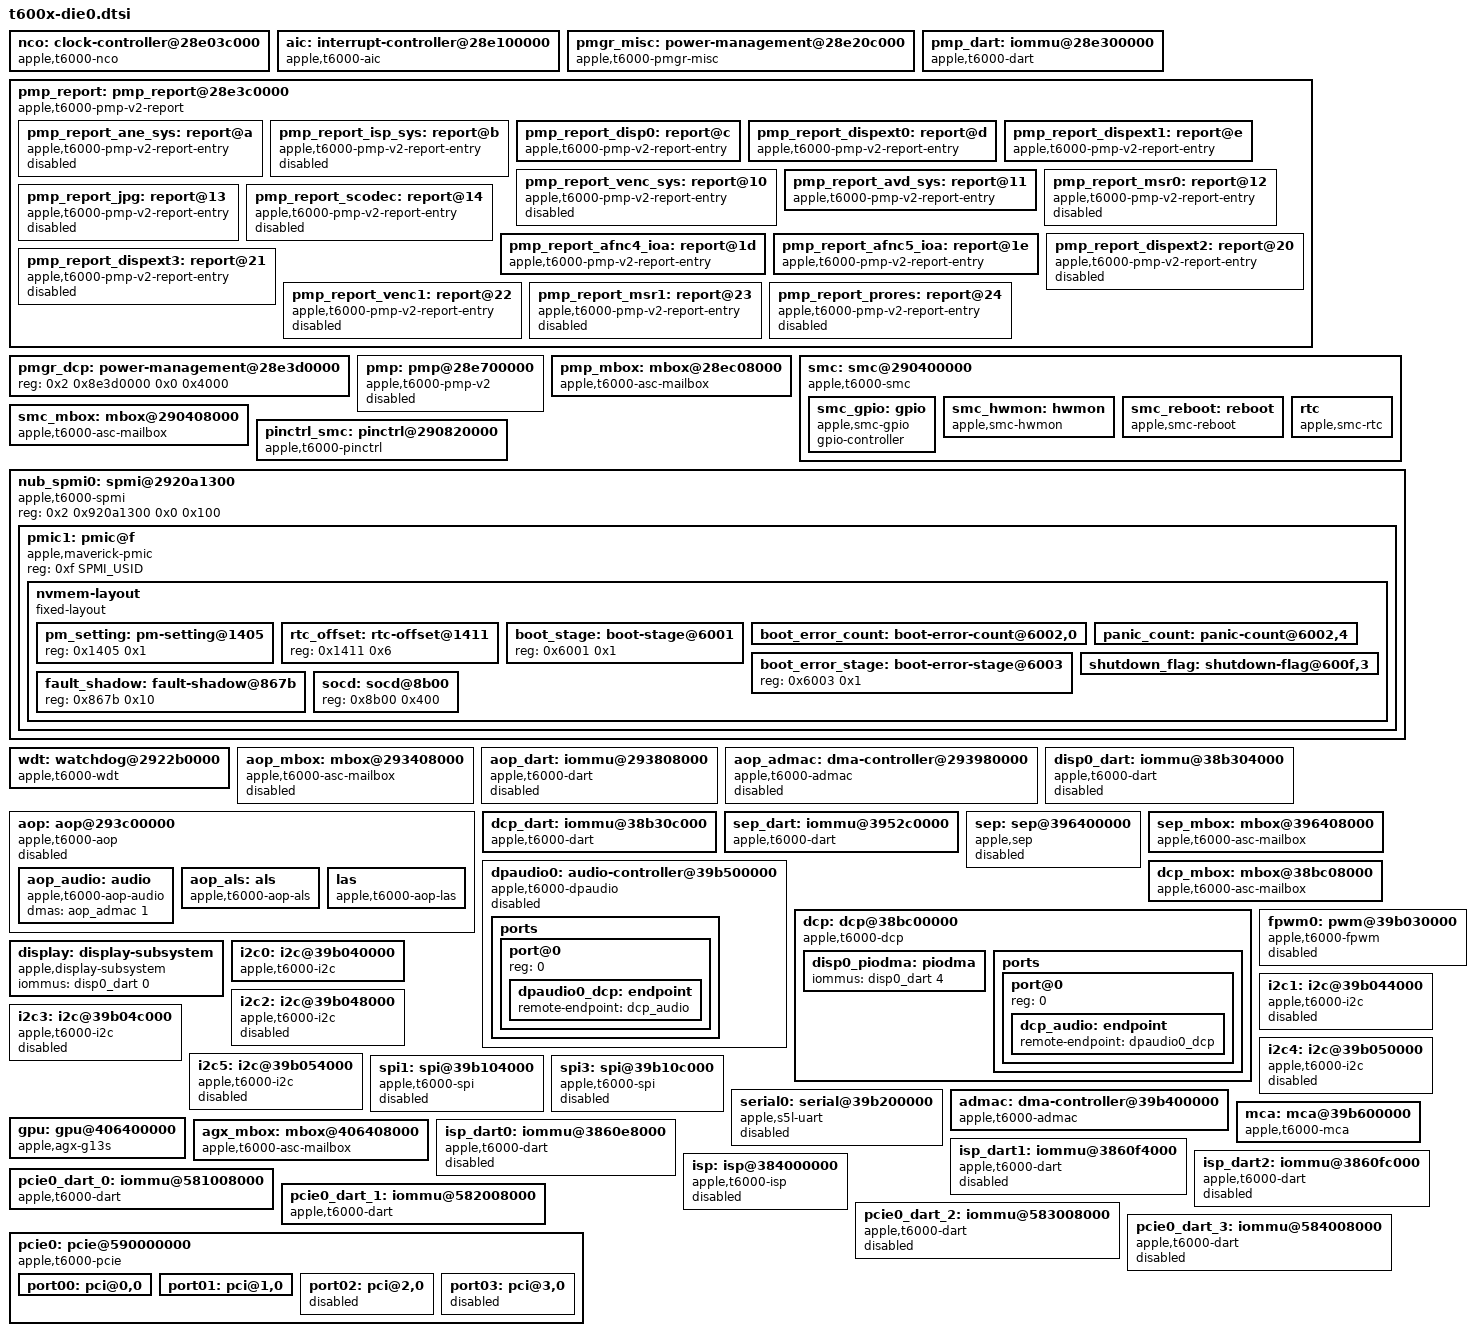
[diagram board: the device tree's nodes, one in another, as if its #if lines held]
// SPDX-License-Identifier: GPL-2.0+ OR MIT
/*
 * Devices used on die 0 on the Apple T6002 "M1 Ultra" SoC and present on
 * Apple T6000 / T6001 "M1 Pro" / "M1 Max".
 *
 * Copyright The Asahi Linux Contributors
 */


	nco: clock-controller@28e03c000 {
		compatible = "apple,t6000-nco", "apple,nco";
		reg = <0x2 0x8e03c000 0x0 0x14000>;
		clocks = <&nco_clkref>;
		#clock-cells = <1>;
	};

	aic: interrupt-controller@28e100000 {
		compatible = "apple,t6000-aic", "apple,aic2";
		#interrupt-cells = <4>;
		interrupt-controller;
		reg = <0x2 0x8e100000 0x0 0xc000>,
			<0x2 0x8e10c000 0x0 0x4>;
		reg-names = "core", "event";
		power-domains = <&ps_aic>;
	};

	pmgr_misc: power-management@28e20c000 {
		compatible = "apple,t6000-pmgr-misc";
		#address-cells = <1>;
		#size-cells = <1>;
		reg = <0x2 0x8e20c000 0 0x400>,
			<0x2 0x8e20c800 0 0x400>;
		reg-names = "fabric-ps", "dcs-ps";
		apple,dcs-min-ps = <7>;
	};

	pmp_dart: iommu@28e300000 {
		compatible = "apple,t6000-dart";
		reg = <0x2 0x8e300000 0x0 0x4000>;
		#iommu-cells = <1>;
		interrupt-parent = <&aic>;
		interrupts = <AIC_IRQ 0 1010 IRQ_TYPE_LEVEL_HIGH>;
		power-domains = <&ps_pmp>;
	};

	pmp_report: pmp_report@28e3c0000 {
		compatible = "apple,t6000-pmp-v2-report";
		reg = <0x2 0x8e3c0000 0x0 0x20000>;
		power-domains = <&ps_pms_sram>;
		#address-cells = <1>;
		#size-cells = <0>;

		pmp_report_ane_sys: report@a {
			compatible = "apple,t6000-pmp-v2-report-entry";
			reg = <0xa>;
			label = "pmp-ane-sys";
			#power-domain-cells = <0>;
			power-domains = <&ps_ane_sys>;
			status = "disabled";
		};

		pmp_report_isp_sys: report@b {
			compatible = "apple,t6000-pmp-v2-report-entry";
			reg = <0xb>;
			label = "pmp-isp-sys";
			#power-domain-cells = <0>;
			power-domains = <&ps_isp_sys>;
			status = "disabled";
		};

		pmp_report_disp0: report@c {
			compatible = "apple,t6000-pmp-v2-report-entry";
			reg = <0xc>;
			label = "pmp-disp0";
			#power-domain-cells = <0>;
			power-domains = <&ps_disp0_cpu0>;
			apple,always-on;
		};

		pmp_report_dispext0: report@d {
			compatible = "apple,t6000-pmp-v2-report-entry";
			reg = <0xd>;
			label = "pmp-dispext0";
			#power-domain-cells = <0>;
			power-domains = <&ps_dispext0_cpu0>;
			apple,always-on;
		};

		pmp_report_dispext1: report@e {
			compatible = "apple,t6000-pmp-v2-report-entry";
			reg = <0xe>;
			label = "pmp-dispext1";
			#power-domain-cells = <0>;
			power-domains = <&ps_dispext1_cpu0>;
		};

		pmp_report_venc_sys: report@10 {
			compatible = "apple,t6000-pmp-v2-report-entry";
			reg = <0x10>;
			label = "pmp-venc-sys";
			#power-domain-cells = <0>;
			power-domains = <&ps_venc_sys>;
			status = "disabled";
		};

		pmp_report_avd_sys: report@11 {
			compatible = "apple,t6000-pmp-v2-report-entry";
			reg = <0x11>;
			label = "pmp-avd-sys";
			#power-domain-cells = <0>;
			power-domains = <&ps_avd_sys>;
		};

		pmp_report_msr0: report@12 {
			compatible = "apple,t6000-pmp-v2-report-entry";
			reg = <0x12>;
			label = "pmp-msr0";
			#power-domain-cells = <0>;
			power-domains = <&ps_msr0>;
			status = "disabled";
		};

		pmp_report_jpg: report@13 {
			compatible = "apple,t6000-pmp-v2-report-entry";
			reg = <0x13>;
			label = "pmp-jpg";
			#power-domain-cells = <0>;
			power-domains = <&ps_jpg>;
			status = "disabled";
		};

		pmp_report_scodec: report@14 {
			compatible = "apple,t6000-pmp-v2-report-entry";
			reg = <0x14>;
			label = "pmp-scodec";
			#power-domain-cells = <0>;
			power-domains = <&ps_scodec>;
			status = "disabled";
		};

		pmp_report_afnc4_ioa: report@1d {
			compatible = "apple,t6000-pmp-v2-report-entry";
			reg = <0x1d>;
			label = "pmp-afnc4-ioa";
			#power-domain-cells = <0>;
			apple,always-on;
		};

		pmp_report_afnc5_ioa: report@1e {
			compatible = "apple,t6000-pmp-v2-report-entry";
			reg = <0x1e>;
			label = "pmp-afnc5-ioa";
			#power-domain-cells = <0>;
			apple,always-on;
		};

		pmp_report_dispext2: report@20 {
			compatible = "apple,t6000-pmp-v2-report-entry";
			reg = <0x20>;
			label = "pmp-dispext2";
			#power-domain-cells = <0>;
			power-domains = <&ps_dispext2_cpu0>;
			status = "disabled";
		};

		pmp_report_dispext3: report@21 {
			compatible = "apple,t6000-pmp-v2-report-entry";
			reg = <0x21>;
			label = "pmp-dispext3";
			#power-domain-cells = <0>;
			power-domains = <&ps_dispext3_cpu0>;
			status = "disabled";
		};

		pmp_report_venc1: report@22 {
			compatible = "apple,t6000-pmp-v2-report-entry";
			reg = <0x22>;
			label = "pmp-venc1";
			#power-domain-cells = <0>;
			power-domains = <&ps_venc1_sys>;
			status = "disabled";
		};

		pmp_report_msr1: report@23 {
			compatible = "apple,t6000-pmp-v2-report-entry";
			reg = <0x23>;
			label = "pmp-msr1";
			#power-domain-cells = <0>;
			power-domains = <&ps_msr1>;
			status = "disabled";
		};

		pmp_report_prores: report@24 {
			compatible = "apple,t6000-pmp-v2-report-entry";
			reg = <0x24>;
			label = "pmp-prores";
			#power-domain-cells = <0>;
			power-domains = <&ps_prores>;
			status = "disabled";
		};
	};

	pmgr_dcp: power-management@28e3d0000 {
		reg = <0x2 0x8e3d0000 0x0 0x4000>;
		reg-names = "dcp-fw-pmgr";
		#apple,bw-scratch-cells = <3>;
	};

	pmp: pmp@28e700000 {
		compatible = "apple,t6000-pmp-v2";
		reg = <0x2 0x8e700000 0x0 0x100000>,
			<0x2 0x8ec00000 0x0 0x4000>;
		reg-names = "pmp", "asc";
		mboxes = <&pmp_mbox>;
		mbox-names = "mbox";
		iommus = <&pmp_dart 0>;
		power-domains = <&ps_pmp>;
		status = "disabled";
	};

	pmp_mbox: mbox@28ec08000 {
		compatible = "apple,t6000-asc-mailbox", "apple,asc-mailbox-v4";
		reg = <0x2 0x8ec08000 0x0 0x4000>;
		interrupt-parent = <&aic>;
		interrupts = <AIC_IRQ 0 1006 IRQ_TYPE_LEVEL_HIGH>,
			<AIC_IRQ 0 1007 IRQ_TYPE_LEVEL_HIGH>,
			<AIC_IRQ 0 1008 IRQ_TYPE_LEVEL_HIGH>,
			<AIC_IRQ 0 1009 IRQ_TYPE_LEVEL_HIGH>;
		interrupt-names = "send-empty", "send-not-empty",
			"recv-empty", "recv-not-empty";
		#mbox-cells = <0>;
		power-domains = <&ps_pmp>, <&ps_pms_sram>;
	};

	smc: smc@290400000 {
		compatible = "apple,t6000-smc", "apple,smc";
		reg = <0x2 0x90400000 0x0 0x4000>,
			<0x2 0x91e00000 0x0 0x100000>;
		reg-names = "smc", "sram";
		mboxes = <&smc_mbox>;

		smc_gpio: gpio {
			compatible = "apple,smc-gpio";
			gpio-controller;
			#gpio-cells = <2>;
		};

		smc_hwmon: hwmon {
			compatible = "apple,smc-hwmon";
		};

		smc_reboot: reboot {
			compatible = "apple,smc-reboot";
			nvmem-cells = <&shutdown_flag>, <&boot_stage>,
				<&boot_error_count>, <&panic_count>, <&pm_setting>;
			nvmem-cell-names = "shutdown_flag", "boot_stage",
				"boot_error_count", "panic_count", "pm_setting";
		};

		rtc {
			compatible = "apple,smc-rtc";
			nvmem-cells = <&rtc_offset>;
			nvmem-cell-names = "rtc_offset";
		};
	};

	smc_mbox: mbox@290408000 {
		compatible = "apple,t6000-asc-mailbox", "apple,asc-mailbox-v4";
		reg = <0x2 0x90408000 0x0 0x4000>;
		interrupt-parent = <&aic>;
		interrupts = <AIC_IRQ 0 754 IRQ_TYPE_LEVEL_HIGH>,
			<AIC_IRQ 0 755 IRQ_TYPE_LEVEL_HIGH>,
			<AIC_IRQ 0 756 IRQ_TYPE_LEVEL_HIGH>,
			<AIC_IRQ 0 757 IRQ_TYPE_LEVEL_HIGH>;
		interrupt-names = "send-empty", "send-not-empty",
			"recv-empty", "recv-not-empty";
		#mbox-cells = <0>;
	};

	pinctrl_smc: pinctrl@290820000 {
		compatible = "apple,t6000-pinctrl", "apple,pinctrl";
		reg = <0x2 0x90820000 0x0 0x4000>;

		gpio-controller;
		#gpio-cells = <2>;
		gpio-ranges = <&pinctrl_smc 0 0 30>;
		apple,npins = <30>;

		interrupt-controller;
		#interrupt-cells = <2>;
		interrupt-parent = <&aic>;
		interrupts = <AIC_IRQ 0 743 IRQ_TYPE_LEVEL_HIGH>,
				<AIC_IRQ 0 744 IRQ_TYPE_LEVEL_HIGH>,
				<AIC_IRQ 0 745 IRQ_TYPE_LEVEL_HIGH>,
				<AIC_IRQ 0 746 IRQ_TYPE_LEVEL_HIGH>,
				<AIC_IRQ 0 747 IRQ_TYPE_LEVEL_HIGH>,
				<AIC_IRQ 0 748 IRQ_TYPE_LEVEL_HIGH>,
				<AIC_IRQ 0 749 IRQ_TYPE_LEVEL_HIGH>;
	};

	nub_spmi0: spmi@2920a1300 {
		compatible = "apple,t6000-spmi", "apple,spmi";
		reg = <0x2 0x920a1300 0x0 0x100>;
		#address-cells = <2>;
		#size-cells = <0>;

		pmic1: pmic@f {
			compatible = "apple,maverick-pmic", "apple,spmi-nvmem";
			reg = <0xf SPMI_USID>;

			nvmem-layout {
				compatible = "fixed-layout";
				#address-cells = <1>;
				#size-cells = <1>;

				pm_setting: pm-setting@1405 {
					reg = <0x1405 0x1>;
				};

				rtc_offset: rtc-offset@1411 {
					reg = <0x1411 0x6>;
				};

				boot_stage: boot-stage@6001 {
					reg = <0x6001 0x1>;
				};

				boot_error_count: boot-error-count@6002,0 {
					reg = <0x6002 0x1>;
					bits = <0 4>;
				};

				panic_count: panic-count@6002,4 {
					reg = <0x6002 0x1>;
					bits = <4 4>;
				};

				boot_error_stage: boot-error-stage@6003 {
					reg = <0x6003 0x1>;
				};

				shutdown_flag: shutdown-flag@600f,3 {
					reg = <0x600f 0x1>;
					bits = <3 1>;
				};

				fault_shadow: fault-shadow@867b {
					reg = <0x867b 0x10>;
				};

				socd: socd@8b00 {
					reg = <0x8b00 0x400>;
				};
			};
		};
	};

	wdt: watchdog@2922b0000 {
		compatible = "apple,t6000-wdt", "apple,wdt";
		reg = <0x2 0x922b0000 0x0 0x4000>;
		clocks = <&clkref>;
		interrupt-parent = <&aic>;
		interrupts = <AIC_IRQ 0 631 IRQ_TYPE_LEVEL_HIGH>;
	};

	aop_mbox: mbox@293408000 {
		compatible = "apple,t6000-asc-mailbox", "apple,asc-mailbox-v4";
		reg = <0x2 0x93408000 0x0 0x4000>;
		interrupt-parent = <&aic>;
		interrupts = <AIC_IRQ 0 582 IRQ_TYPE_LEVEL_HIGH>,
			<AIC_IRQ 0 583 IRQ_TYPE_LEVEL_HIGH>,
			<AIC_IRQ 0 584 IRQ_TYPE_LEVEL_HIGH>,
			<AIC_IRQ 0 585 IRQ_TYPE_LEVEL_HIGH>;
		interrupt-names = "send-empty", "send-not-empty",
			"recv-empty", "recv-not-empty";
		#mbox-cells = <0>;
		status = "disabled";
	};

	aop_dart: iommu@293808000 {
		compatible = "apple,t6000-dart";
		reg = <0x2 0x93808000 0x0 0x4000>;
		#iommu-cells = <1>;
		interrupt-parent = <&aic>;
		interrupts = <AIC_IRQ 0 597 IRQ_TYPE_LEVEL_HIGH>;
		status = "disabled";
	};

	aop_admac: dma-controller@293980000 {
		compatible = "apple,t6000-admac", "apple,admac";
		reg = <0x2 0x93980000 0x0 0x34000>;
		#dma-cells = <1>;
		dma-channels = <16>;
		interrupts-extended = <0>,
				      <0>,
				      <&aic AIC_IRQ 0 600 IRQ_TYPE_LEVEL_HIGH>,
				      <0>;
		iommus = <&aop_dart 7>;
		status = "disabled";
	};

	aop: aop@293c00000 {
		compatible = "apple,t6000-aop";
		reg = <0x2 0x93c00000 0x0 0x250000>,
		      <0x2 0x93400000 0x0 0x6c000>;
		mboxes = <&aop_mbox>;
		mbox-names = "mbox";
		iommus = <&aop_dart 0>;

		status = "disabled";

		aop_audio: audio {
			compatible = "apple,t6000-aop-audio", "apple,aop-audio";
			dmas = <&aop_admac 1>;
			dma-names = "dma";
		};

		aop_als: als {
			compatible = "apple,t6000-aop-als", "apple,aop-als";
			// intentionally empty
		};

		las {
			compatible = "apple,t6000-aop-las", "apple,aop-las";
		};
	};

	disp0_dart: iommu@38b304000 {
		compatible = "apple,t6000-dart";
		reg = <0x3 0x8b304000 0x0 0x4000>;
		#iommu-cells = <1>;
		interrupt-parent = <&aic>;
		interrupts = <AIC_IRQ 0 821 IRQ_TYPE_LEVEL_HIGH>;
		status = "disabled";
		power-domains = <&ps_disp0_cpu0>;
		apple,dma-range = <0x0 0x0 0x0 0xfc000000>;
	};

	dcp_dart: iommu@38b30c000 {
		compatible = "apple,t6000-dart";
		reg = <0x3 0x8b30c000 0x0 0x4000>;
		#iommu-cells = <1>;
		interrupt-parent = <&aic>;
		interrupts = <AIC_IRQ 0 821 IRQ_TYPE_LEVEL_HIGH>;
		power-domains = <&ps_disp0_cpu0>;
		apple,dma-range = <0x1f0 0x0 0x0 0xfc000000>;
	};

	sep_dart: iommu@3952c0000 {
		compatible = "apple,t6000-dart";
		reg = <0x3 0x952c0000 0x0 0x4000>;
		#iommu-cells = <1>;
		interrupt-parent = <&aic>;
		interrupts = <AIC_IRQ 0 551 IRQ_TYPE_LEVEL_HIGH>;
	};

	sep: sep@396400000 {
		compatible = "apple,sep";
		reg = <0x3 0x96400000 0x0 0x6C000>;
		mboxes = <&sep_mbox>;
		mbox-names = "mbox";
		iommus = <&sep_dart 0>;
		power-domains = <&ps_sep>;
		status = "disabled";
	};

	sep_mbox: mbox@396408000 {
		compatible = "apple,t6000-asc-mailbox", "apple,asc-mailbox-v4";
		reg = <0x3 0x96408000 0x0 0x4000>;
		interrupt-parent = <&aic>;
		interrupts = <AIC_IRQ 0 545 IRQ_TYPE_LEVEL_HIGH>,
			<AIC_IRQ 0 546 IRQ_TYPE_LEVEL_HIGH>,
			<AIC_IRQ 0 547 IRQ_TYPE_LEVEL_HIGH>,
			<AIC_IRQ 0 548 IRQ_TYPE_LEVEL_HIGH>;
		interrupt-names = "send-empty", "send-not-empty",
			"recv-empty", "recv-not-empty";
		#mbox-cells = <0>;
	};

	dpaudio0: audio-controller@39b500000 {
		compatible = "apple,t6000-dpaudio", "apple,dpaudio";
		reg = <0x3 0x9b500000 0x0 0x4000>;
		dmas = <&sio 0x64>;
		dma-names = "tx";
		power-domains = <&ps_dpa0>;
		reset-domains = <&ps_dpa0>;
		status = "disabled";

		ports {
			#address-cells = <1>;
			#size-cells = <0>;
			port@0 {
				reg = <0>;
				dpaudio0_dcp: endpoint {
					remote-endpoint = <&dcp_audio>;
				};
			};
		};
	};

	dcp_mbox: mbox@38bc08000 {
		compatible = "apple,t6000-asc-mailbox", "apple,asc-mailbox-v4";
		reg = <0x3 0x8bc08000 0x0 0x4000>;
		interrupt-parent = <&aic>;
		interrupts = <AIC_IRQ 0 842 IRQ_TYPE_LEVEL_HIGH>,
			<AIC_IRQ 0 843 IRQ_TYPE_LEVEL_HIGH>,
			<AIC_IRQ 0 844 IRQ_TYPE_LEVEL_HIGH>,
			<AIC_IRQ 0 845 IRQ_TYPE_LEVEL_HIGH>;
		interrupt-names = "send-empty", "send-not-empty",
			"recv-empty", "recv-not-empty";
		#mbox-cells = <0>;
		power-domains = <&ps_disp0_cpu0>;
	};

	dcp: dcp@38bc00000 {
		compatible = "apple,t6000-dcp", "apple,dcp";
		mboxes = <&dcp_mbox>;
		mbox-names = "mbox";
		iommus = <&dcp_dart 0>;

		reg-names = "coproc", "disp-0", "disp-1", "disp-2", "disp-3";
		reg = <0x3 0x8bc00000 0x0 0x4000>,
			<0x3 0x8a000000 0x0 0x3000000>,
			<0x3 0x8b320000 0x0 0x4000>,
			<0x3 0x8b344000 0x0 0x4000>,
			<0x3 0x8b800000 0x0 0x800000>;
		apple,bw-scratch = <&pmgr_dcp 0 4 0x988>;
		#ifdef APPLE_USE_PMP
		power-domains = <&pmp_report_disp0>;
		#else
		power-domains = <&ps_disp0_cpu0>;
		#endif
		resets = <&ps_disp0_cpu0>;
		clocks = <&clk_disp0>;
		phandle = <&dcp>;
		// required bus properties for 'piodma' subdevice
		#address-cells = <2>;
		#size-cells = <2>;

		disp0_piodma: piodma {
			iommus = <&disp0_dart 4>;
			phandle = <&disp0_piodma>;
		};

		ports {
			#address-cells = <1>;
			#size-cells = <0>;
			port@0 {
				reg = <0>;
				dcp_audio: endpoint {
					remote-endpoint = <&dpaudio0_dcp>;
				};
			};
		};
	};

	display: display-subsystem {
		compatible = "apple,display-subsystem";
		iommus = <&disp0_dart 0>;
		/* generate phandle explicitly for use in loader */
		phandle = <&display>;
	};

	fpwm0: pwm@39b030000 {
		compatible = "apple,t6000-fpwm", "apple,s5l-fpwm";
		reg = <0x3 0x9b030000 0x0 0x4000>;
		power-domains = <&ps_fpwm0>;
		clocks = <&clkref>;
		#pwm-cells = <2>;
		status = "disabled";
	};

	i2c0: i2c@39b040000 {
		compatible = "apple,t6000-i2c", "apple,i2c";
		reg = <0x3 0x9b040000 0x0 0x4000>;
		clocks = <&clkref>;
		interrupt-parent = <&aic>;
		interrupts = <AIC_IRQ 0 1119 IRQ_TYPE_LEVEL_HIGH>;
		pinctrl-0 = <&i2c0_pins>;
		pinctrl-names = "default";
		power-domains = <&ps_i2c0>;
		#address-cells = <0x1>;
		#size-cells = <0x0>;
	};

	i2c1: i2c@39b044000 {
		compatible = "apple,t6000-i2c", "apple,i2c";
		reg = <0x3 0x9b044000 0x0 0x4000>;
		clocks = <&clkref>;
		interrupt-parent = <&aic>;
		interrupts = <AIC_IRQ 0 1120 IRQ_TYPE_LEVEL_HIGH>;
		pinctrl-0 = <&i2c1_pins>;
		pinctrl-names = "default";
		power-domains = <&ps_i2c1>;
		#address-cells = <0x1>;
		#size-cells = <0x0>;
		status = "disabled";
	};

	i2c2: i2c@39b048000 {
		compatible = "apple,t6000-i2c", "apple,i2c";
		reg = <0x3 0x9b048000 0x0 0x4000>;
		clocks = <&clkref>;
		interrupt-parent = <&aic>;
		interrupts = <AIC_IRQ 0 1121 IRQ_TYPE_LEVEL_HIGH>;
		pinctrl-0 = <&i2c2_pins>;
		pinctrl-names = "default";
		power-domains = <&ps_i2c2>;
		#address-cells = <0x1>;
		#size-cells = <0x0>;
		status = "disabled";
	};

	i2c3: i2c@39b04c000 {
		compatible = "apple,t6000-i2c", "apple,i2c";
		reg = <0x3 0x9b04c000 0x0 0x4000>;
		clocks = <&clkref>;
		interrupt-parent = <&aic>;
		interrupts = <AIC_IRQ 0 1122 IRQ_TYPE_LEVEL_HIGH>;
		pinctrl-0 = <&i2c3_pins>;
		pinctrl-names = "default";
		power-domains = <&ps_i2c3>;
		#address-cells = <0x1>;
		#size-cells = <0x0>;
		status = "disabled";
	};

	i2c4: i2c@39b050000 {
		compatible = "apple,t6000-i2c", "apple,i2c";
		reg = <0x3 0x9b050000 0x0 0x4000>;
		clocks = <&clkref>;
		interrupt-parent = <&aic>;
		interrupts = <AIC_IRQ 0 1123 IRQ_TYPE_LEVEL_HIGH>;
		pinctrl-0 = <&i2c4_pins>;
		pinctrl-names = "default";
		power-domains = <&ps_i2c4>;
		#address-cells = <0x1>;
		#size-cells = <0x0>;
		status = "disabled";
	};

	i2c5: i2c@39b054000 {
		compatible = "apple,t6000-i2c", "apple,i2c";
		reg = <0x3 0x9b054000 0x0 0x4000>;
		clocks = <&clkref>;
		interrupt-parent = <&aic>;
		interrupts = <AIC_IRQ 0 1124 IRQ_TYPE_LEVEL_HIGH>;
		pinctrl-0 = <&i2c5_pins>;
		pinctrl-names = "default";
		power-domains = <&ps_i2c5>;
		#address-cells = <0x1>;
		#size-cells = <0x0>;
		status = "disabled";
	};

	spi1: spi@39b104000 {
		compatible = "apple,t6000-spi", "apple,spi";
		reg = <0x3 0x9b104000 0x0 0x4000>;
		interrupt-parent = <&aic>;
		interrupts = <AIC_IRQ 0 1107 IRQ_TYPE_LEVEL_HIGH>;
		#address-cells = <1>;
		#size-cells = <0>;
		clocks = <&clk_200m>;
		pinctrl-0 = <&spi1_pins>;
		pinctrl-names = "default";
		power-domains = <&ps_spi1>;
		status = "disabled";
	};

	spi3: spi@39b10c000 {
		compatible = "apple,t6000-spi", "apple,spi";
		reg = <0x3 0x9b10c000 0x0 0x4000>;
		interrupt-parent = <&aic>;
		interrupts = <AIC_IRQ 0 1109 IRQ_TYPE_LEVEL_HIGH>;
		#address-cells = <1>;
		#size-cells = <0>;
		clocks = <&clkref>;
		pinctrl-0 = <&spi3_pins>;
		pinctrl-names = "default";
		power-domains = <&ps_spi3>;
		status = "disabled";
	};

	serial0: serial@39b200000 {
		compatible = "apple,s5l-uart";
		reg = <0x3 0x9b200000 0x0 0x1000>;
		reg-io-width = <4>;
		interrupt-parent = <&aic>;
		interrupts = <AIC_IRQ 0 1097 IRQ_TYPE_LEVEL_HIGH>;
		/*
		 * TODO: figure out the clocking properly, there may
		 * be a third selectable clock.
		 */
		clocks = <&clkref>, <&clkref>;
		clock-names = "uart", "clk_uart_baud0";
		power-domains = <&ps_uart0>;
		status = "disabled";
	};

	admac: dma-controller@39b400000 {
		compatible = "apple,t6000-admac", "apple,admac";
		reg = <0x3 0x9b400000 0x0 0x34000>;
		#dma-cells = <1>;
		dma-channels = <16>;
		interrupts-extended = <0>,
				      <&aic AIC_IRQ 0 1118 IRQ_TYPE_LEVEL_HIGH>,
				      <0>,
				      <0>;
		iommus = <&sio_dart_0 2>, <&sio_dart_1 2>;
		power-domains = <&ps_sio_adma>;
		resets = <&ps_audio_p>;
	};

	mca: mca@39b600000 {
		compatible = "apple,t6000-mca", "apple,mca";
		reg = <0x3 0x9b600000 0x0 0x10000>,
		      <0x3 0x9b500000 0x0 0x20000>;
		clocks = <&nco 0>, <&nco 1>, <&nco 2>, <&nco 3>;
		dmas = <&admac 0>, <&admac 1>, <&admac 2>, <&admac 3>,
		       <&admac 4>, <&admac 5>, <&admac 6>, <&admac 7>,
		       <&admac 8>, <&admac 9>, <&admac 10>, <&admac 11>,
		       <&admac 12>, <&admac 13>, <&admac 14>, <&admac 15>;
		dma-names = "tx0a", "rx0a", "tx0b", "rx0b",
			    "tx1a", "rx1a", "tx1b", "rx1b",
			    "tx2a", "rx2a", "tx2b", "rx2b",
			    "tx3a", "rx3a", "tx3b", "rx3b";
		interrupt-parent = <&aic>;
		interrupts = <AIC_IRQ 0 1111 IRQ_TYPE_LEVEL_HIGH>,
			     <AIC_IRQ 0 1112 IRQ_TYPE_LEVEL_HIGH>,
			     <AIC_IRQ 0 1113 IRQ_TYPE_LEVEL_HIGH>,
			     <AIC_IRQ 0 1114 IRQ_TYPE_LEVEL_HIGH>;
		power-domains = <&ps_audio_p>, <&ps_mca0>, <&ps_mca1>,
				<&ps_mca2>, <&ps_mca3>;
		resets = <&ps_audio_p>;
		#sound-dai-cells = <1>;
	};

	gpu: gpu@406400000 {
		compatible = "apple,agx-g13s";
		reg = <0x4 0x6400000 0 0x40000>,
			<0x4 0x4000000 0 0x1000000>;
		reg-names = "asc", "sgx";
		mboxes = <&agx_mbox>;
		power-domains = <&ps_gfx>;
		memory-region = <&uat_ttbs>, <&uat_pagetables>, <&uat_handoff>,
				<&gpu_hw_cal_a>, <&gpu_hw_cal_b>, <&gpu_globals>;
		memory-region-names = "ttbs", "pagetables", "handoff",
				      "hw-cal-a", "hw-cal-b", "globals";

		apple,firmware-abi = <0 0 0>;

		apple,firmware-version = <12 3 0>;
		apple,firmware-compat = <12 3 0>;

		operating-points-v2 = <&gpu_opp>;
		apple,perf-base-pstate = <1>;
		apple,min-sram-microvolt = <790000>;
		apple,avg-power-filter-tc-ms = <1000>;
		apple,avg-power-ki-only = <2.4>;
		apple,avg-power-kp = <1.5>;
		apple,avg-power-min-duty-cycle = <40>;
		apple,avg-power-target-filter-tc = <125>;
		apple,fast-die0-integral-gain = <500.0>;
		apple,fast-die0-proportional-gain = <72.0>;
		apple,perf-boost-ce-step = <50>;
		apple,perf-boost-min-util = <90>;
		apple,perf-filter-drop-threshold = <0>;
		apple,perf-filter-time-constant = <5>;
		apple,perf-filter-time-constant2 = <50>;
		apple,perf-integral-gain = <6.3>;
		apple,perf-integral-gain2 = <0.197392>;
		apple,perf-integral-min-clamp = <0>;
		apple,perf-proportional-gain = <15.75>;
		apple,perf-proportional-gain2 = <6.853981>;
		apple,perf-tgt-utilization = <85>;
		apple,power-sample-period = <8>;
		apple,ppm-filter-time-constant-ms = <100>;
		apple,ppm-ki = <30.0>;
		apple,ppm-kp = <1.5>;
		apple,pwr-filter-time-constant = <313>;
		apple,pwr-integral-gain = <0.0202129>;
		apple,pwr-integral-min-clamp = <0>;
		apple,pwr-min-duty-cycle = <40>;
		apple,pwr-proportional-gain = <5.2831855>;

		apple,core-leak-coef = GPU_REPEAT(1200.0);
		apple,sram-leak-coef = GPU_REPEAT(20.0);
	};

	agx_mbox: mbox@406408000 {
		compatible = "apple,t6000-asc-mailbox", "apple,asc-mailbox-v4";
		reg = <0x4 0x6408000 0x0 0x4000>;
		interrupt-parent = <&aic>;
		interrupts = <AIC_IRQ 0 1059 IRQ_TYPE_LEVEL_HIGH>,
			<AIC_IRQ 0 1060 IRQ_TYPE_LEVEL_HIGH>,
			<AIC_IRQ 0 1061 IRQ_TYPE_LEVEL_HIGH>,
			<AIC_IRQ 0 1062 IRQ_TYPE_LEVEL_HIGH>;
		interrupt-names = "send-empty", "send-not-empty",
			"recv-empty", "recv-not-empty";
		#mbox-cells = <0>;
	};

	isp_dart0: iommu@3860e8000 {
		compatible = "apple,t6000-dart";
		reg = <0x3 0x860e8000 0x0 0x4000>;
		#iommu-cells = <1>;
		interrupt-parent = <&aic>;
		interrupts = <AIC_IRQ 0 543 IRQ_TYPE_LEVEL_HIGH>;
		power-domains = <&ps_isp_sys>;
		status = "disabled";
	};

	isp_dart1: iommu@3860f4000 {
		compatible = "apple,t6000-dart";
		reg = <0x3 0x860f4000 0x0 0x4000>;
		#iommu-cells = <1>;
		interrupt-parent = <&aic>;
		interrupts = <AIC_IRQ 0 543 IRQ_TYPE_LEVEL_HIGH>;
		power-domains = <&ps_isp_sys>;
		status = "disabled";
	};

	isp_dart2: iommu@3860fc000 {
		compatible = "apple,t6000-dart";
		reg = <0x3 0x860fc000 0x0 0x4000>;
		#iommu-cells = <1>;
		interrupt-parent = <&aic>;
		interrupts = <AIC_IRQ 0 543 IRQ_TYPE_LEVEL_HIGH>;
		power-domains = <&ps_isp_sys>;
		status = "disabled";
	};

	isp: isp@384000000 {
		compatible = "apple,t6000-isp", "apple,isp";
		iommus = <&isp_dart0 0>, <&isp_dart1 0>, <&isp_dart2 0>;
		reg-names = "coproc", "mbox", "gpio", "mbox2";
		reg = <0x3 0x84000000 0x0 0x2000000>,
			<0x3 0x86104000 0x0 0x100>,
			<0x3 0x86104170 0x0 0x100>,
			<0x3 0x861043f0 0x0 0x100>;
		interrupt-parent = <&aic>;
		interrupts = <AIC_IRQ 0 538 IRQ_TYPE_LEVEL_HIGH>;
		#ifdef APPLE_USE_PMP
		power-domains = <&pmp_report_isp_sys>, <&ps_isp_set0>,
		#else
		power-domains = <&ps_isp_sys>, <&ps_isp_set0>,
		#endif
			<&ps_isp_set1>, <&ps_isp_fe>, <&ps_isp_set3>,
			<&ps_isp_set4>, <&ps_isp_set5>, <&ps_isp_set6>,
			<&ps_isp_set7>, <&ps_isp_set8>;
		apple,dart-vm-size = <0x0 0xa0000000>;

		status = "disabled";
	};

	pcie0_dart_0: iommu@581008000 {
		compatible = "apple,t6000-dart";
		reg = <0x5 0x81008000 0x0 0x4000>;
		#iommu-cells = <1>;
		interrupt-parent = <&aic>;
		interrupts = <AIC_IRQ 0 1271 IRQ_TYPE_LEVEL_HIGH>;
		power-domains = <&ps_apcie_gp_sys>;
	};

	pcie0_dart_1: iommu@582008000 {
		compatible = "apple,t6000-dart";
		reg = <0x5 0x82008000 0x0 0x4000>;
		#iommu-cells = <1>;
		interrupt-parent = <&aic>;
		interrupts = <AIC_IRQ 0 1274 IRQ_TYPE_LEVEL_HIGH>;
		power-domains = <&ps_apcie_gp_sys>;
	};

	pcie0_dart_2: iommu@583008000 {
		compatible = "apple,t6000-dart";
		reg = <0x5 0x83008000 0x0 0x4000>;
		#iommu-cells = <1>;
		interrupt-parent = <&aic>;
		interrupts = <AIC_IRQ 0 1277 IRQ_TYPE_LEVEL_HIGH>;
		power-domains = <&ps_apcie_gp_sys>;
		status = "disabled";
	};

	pcie0_dart_3: iommu@584008000 {
		compatible = "apple,t6000-dart";
		reg = <0x5 0x84008000 0x0 0x4000>;
		#iommu-cells = <1>;
		interrupt-parent = <&aic>;
		interrupts = <AIC_IRQ 0 1280 IRQ_TYPE_LEVEL_HIGH>;
		power-domains = <&ps_apcie_gp_sys>;
		status = "disabled";
	};

	pcie0: pcie@590000000 {
		compatible = "apple,t6000-pcie", "apple,pcie";
		device_type = "pci";

		reg = <0x5 0x90000000 0x0 0x1000000>,
			<0x5 0x80000000 0x0 0x100000>,
			<0x5 0x81000000 0x0 0x4000>,
			<0x5 0x82000000 0x0 0x4000>,
			<0x5 0x83000000 0x0 0x4000>,
			<0x5 0x84000000 0x0 0x4000>;
		reg-names = "config", "rc", "port0", "port1", "port2", "port3";

		interrupt-parent = <&aic>;
		interrupts = <AIC_IRQ 0 1270 IRQ_TYPE_LEVEL_HIGH>,
				<AIC_IRQ 0 1273 IRQ_TYPE_LEVEL_HIGH>,
				<AIC_IRQ 0 1276 IRQ_TYPE_LEVEL_HIGH>,
				<AIC_IRQ 0 1279 IRQ_TYPE_LEVEL_HIGH>;

		msi-controller;
		msi-parent = <&pcie0>;
		msi-ranges = <&aic AIC_IRQ 0 1581 IRQ_TYPE_EDGE_RISING 32>;


		iommu-map = <0x100 &pcie0_dart_0 1 1>,
				<0x200 &pcie0_dart_1 1 1>,
				<0x300 &pcie0_dart_2 1 1>,
				<0x400 &pcie0_dart_3 1 1>;
		iommu-map-mask = <0xff00>;

		bus-range = <0 4>;
		#address-cells = <3>;
		#size-cells = <2>;
		ranges = <0x43000000 0x5 0xa0000000 0x5 0xa0000000 0x0 0x20000000>,
				<0x02000000 0x0 0xc0000000 0x5 0xc0000000 0x0 0x40000000>;

		power-domains = <&ps_apcie_gp_sys>;
		pinctrl-0 = <&pcie_pins>;
		pinctrl-names = "default";

		dma-coherent;

		port00: pci@0,0 {
			device_type = "pci";
			reg = <0x0 0x0 0x0 0x0 0x0>;
			reset-gpios = <&pinctrl_ap 4 GPIO_ACTIVE_LOW>;

			#address-cells = <3>;
			#size-cells = <2>;
			ranges;

			interrupt-controller;
			#interrupt-cells = <1>;

			interrupt-map-mask = <0 0 0 7>;
			interrupt-map = <0 0 0 1 &port00 0 0 0 0>,
					<0 0 0 2 &port00 0 0 0 1>,
					<0 0 0 3 &port00 0 0 0 2>,
					<0 0 0 4 &port00 0 0 0 3>;
		};

		port01: pci@1,0 {
			device_type = "pci";
			reg = <0x800 0x0 0x0 0x0 0x0>;
			reset-gpios = <&pinctrl_ap 5 GPIO_ACTIVE_LOW>;

			#address-cells = <3>;
			#size-cells = <2>;
			ranges;

			interrupt-controller;
			#interrupt-cells = <1>;

			interrupt-map-mask = <0 0 0 7>;
			interrupt-map = <0 0 0 1 &port01 0 0 0 0>,
					<0 0 0 2 &port01 0 0 0 1>,
					<0 0 0 3 &port01 0 0 0 2>,
					<0 0 0 4 &port01 0 0 0 3>;
		};

		port02: pci@2,0 {
			device_type = "pci";
			reg = <0x1000 0x0 0x0 0x0 0x0>;
			reset-gpios = <&pinctrl_ap 6 GPIO_ACTIVE_LOW>;

			#address-cells = <3>;
			#size-cells = <2>;
			ranges;

			interrupt-controller;
			#interrupt-cells = <1>;

			interrupt-map-mask = <0 0 0 7>;
			interrupt-map = <0 0 0 1 &port02 0 0 0 0>,
					<0 0 0 2 &port02 0 0 0 1>,
					<0 0 0 3 &port02 0 0 0 2>,
					<0 0 0 4 &port02 0 0 0 3>;
			status = "disabled";
		};

		port03: pci@3,0 {
			device_type = "pci";
			reg = <0x1800 0x0 0x0 0x0 0x0>;
			reset-gpios = <&pinctrl_ap 7 GPIO_ACTIVE_LOW>;

			#address-cells = <3>;
			#size-cells = <2>;
			ranges;

			interrupt-controller;
			#interrupt-cells = <1>;

			interrupt-map-mask = <0 0 0 7>;
			interrupt-map = <0 0 0 1 &port03 0 0 0 0>,
					<0 0 0 2 &port03 0 0 0 1>,
					<0 0 0 3 &port03 0 0 0 2>,
					<0 0 0 4 &port03 0 0 0 3>;
			status = "disabled";
		};
	};
